# iom480ae register map
Registers are 32-bit, access not given, no defined reset value unless marked. A register's access mark holds for its fields unless they carry their own. Addresses are absolute; registers are grouped by the start of their names; [hi:lo] are bit positions; {n}, {i} and the like mark numbered series; 'fields as' and 'values as' point back to an identical list.

## EBI
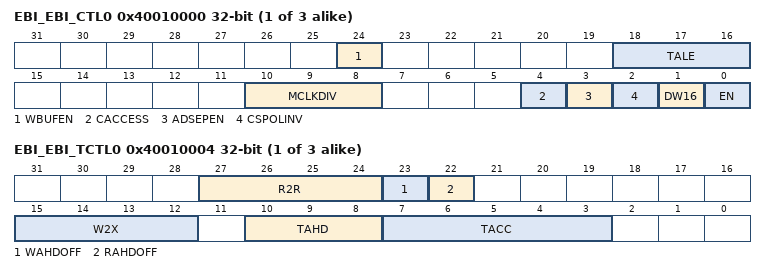
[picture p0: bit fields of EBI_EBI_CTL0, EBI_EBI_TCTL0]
{0x40010000+0x10*i} EBI_EBI_CTL{i} (i=0..2)
  [24] WBUFEN, [18:16] TALE, [10:8] MCLKDIV, [4] CACCESS, [3] ADSEPEN, [2] CSPOLINV, [1] DW16, [0] EN
{0x40010004+0x10*i} EBI_EBI_TCTL{i} (i=0..2)
  [27:24] R2R, [23] WAHDOFF, [22] RAHDOFF, [15:12] W2X, [10:8] TAHD, [7:3] TACC

## USBD
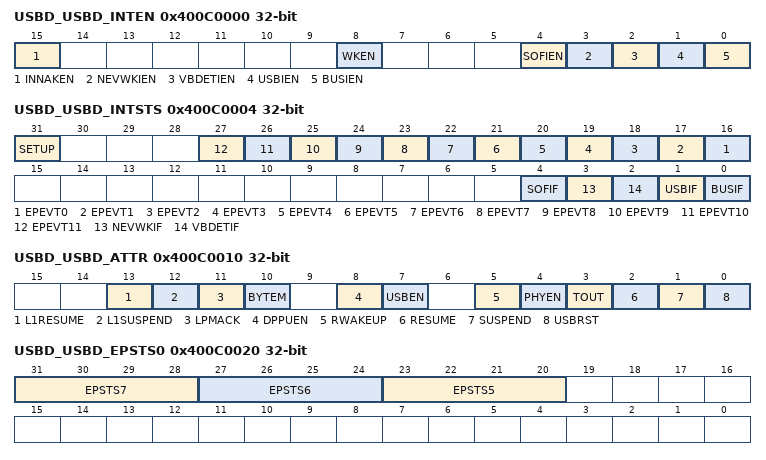
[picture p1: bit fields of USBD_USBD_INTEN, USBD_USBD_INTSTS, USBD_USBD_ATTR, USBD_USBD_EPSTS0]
0x400C0000 USBD_USBD_INTEN
  [15] INNAKEN, [8] WKEN, [4] SOFIEN, [3] NEVWKIEN, [2] VBDETIEN, [1] USBIEN, [0] BUSIEN
0x400C0004 USBD_USBD_INTSTS
  [31] SETUP, [n+16] EPEVT{n} (n=0..11), [4] SOFIF, [3] NEVWKIF, [2] VBDETIF, [1] USBIF, [0] BUSIF
0x400C0008 USBD_USBD_FADDR
  [6:0] FADDR
0x400C000C USBD_USBD_EPSTS
  [7] OV
0x400C0010 USBD_USBD_ATTR
  [13] L1RESUME, [12] L1SUSPEND, [11] LPMACK, [10] BYTEM, [8] DPPUEN, [7] USBEN, [5] RWAKEUP, [4] PHYEN, [3] TOUT, [2] RESUME, [1] SUSPEND, [0] USBRST
0x400C0014 USBD_USBD_VBUSDET
  [0] VBUSDET
0x400C0018 USBD_USBD_STBUFSEG
  [8:3] STBUFSEG
0x400C0020 USBD_USBD_EPSTS0
  [31:28] EPSTS7, [27:24] EPSTS6, [23:20] EPSTS5
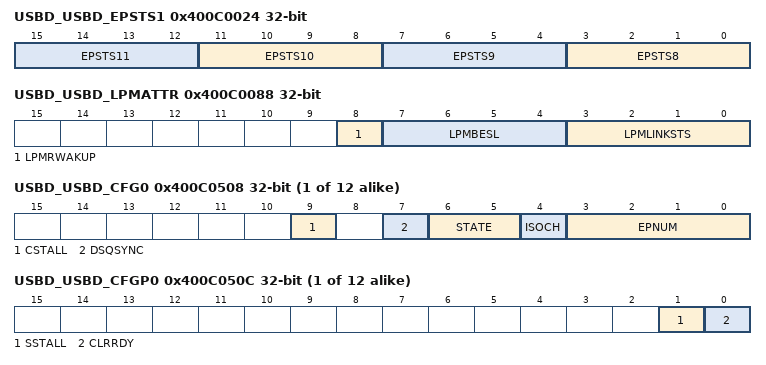
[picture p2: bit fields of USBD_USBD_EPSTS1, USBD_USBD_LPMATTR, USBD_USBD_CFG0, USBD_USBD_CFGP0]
0x400C0024 USBD_USBD_EPSTS1
  [4n-29:4n-32] EPSTS{n} (n=8..11)
0x400C0088 USBD_USBD_LPMATTR
  [8] LPMRWAKUP, [7:4] LPMBESL, [3:0] LPMLINKSTS
0x400C008C USBD_USBD_FN
  [10:0] FN
0x400C0090 USBD_USBD_SE0
  [0] SE0
{0x400C0500+0x10*i} USBD_USBD_BUFSEG{i} (i=0..11)
  [8:3] BUFSEG
{0x400C0504+0x10*i} USBD_USBD_MXPLD{i} (i=0..11)
  [8:0] MXPLD
{0x400C0508+0x10*i} USBD_USBD_CFG{i} (i=0..11)
  [9] CSTALL, [7] DSQSYNC, [6:5] STATE, [4] ISOCH, [3:0] EPNUM
{0x400C050C+0x10*i} USBD_USBD_CFGP{i} (i=0..11)
  [1] SSTALL, [0] CLRRDY

## HSUSBH
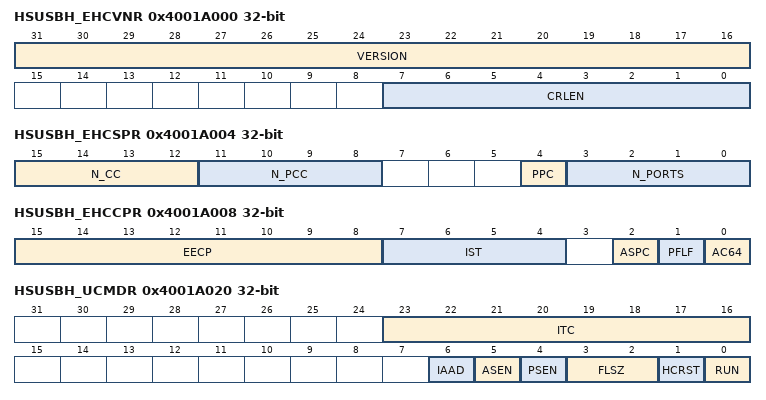
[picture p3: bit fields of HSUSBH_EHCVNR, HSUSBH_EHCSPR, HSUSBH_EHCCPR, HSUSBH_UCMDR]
0x4001A000 HSUSBH_EHCVNR
  [31:16] VERSION, [7:0] CRLEN
0x4001A004 HSUSBH_EHCSPR
  [15:12] N_CC, [11:8] N_PCC, [4] PPC, [3:0] N_PORTS
0x4001A008 HSUSBH_EHCCPR
  [15:8] EECP, [7:4] IST, [2] ASPC, [1] PFLF, [0] AC64
0x4001A020 HSUSBH_UCMDR
  [23:16] ITC, [6] IAAD, [5] ASEN, [4] PSEN, [3:2] FLSZ, [1] HCRST, [0] RUN
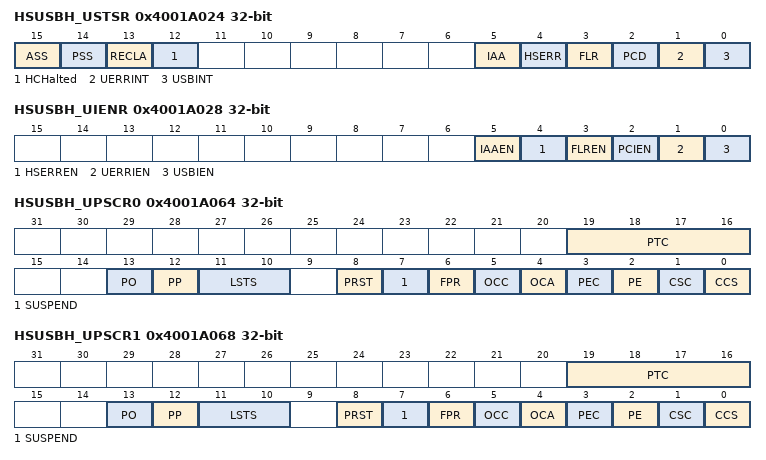
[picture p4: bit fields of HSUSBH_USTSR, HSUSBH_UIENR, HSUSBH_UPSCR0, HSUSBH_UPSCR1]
0x4001A024 HSUSBH_USTSR
  [15] ASS, [14] PSS, [13] RECLA, [12] HCHalted, [5] IAA, [4] HSERR, [3] FLR, [2] PCD, [1] UERRINT, [0] USBINT
0x4001A028 HSUSBH_UIENR
  [5] IAAEN, [4] HSERREN, [3] FLREN, [2] PCIEN, [1] UERRIEN, [0] USBIEN
0x4001A02C HSUSBH_UFINDR
  [13:0] FI
0x4001A034 HSUSBH_UPFLBAR
  [31:12] BADDR
0x4001A038 HSUSBH_UCALAR
  [31:5] LPL
0x4001A03C HSUSBH_UASSTR
  [11:0] ASSTMR
0x4001A060 HSUSBH_UCFGR
  [0] CF
0x4001A064 HSUSBH_UPSCR0
  [19:16] PTC, [13] PO, [12] PP, [11:10] LSTS, [8] PRST, [7] SUSPEND, [6] FPR, [5] OCC, [4] OCA, [3] PEC, [2] PE, [1] CSC, [0] CCS
0x4001A068 HSUSBH_UPSCR1
  fields as HSUSBH_UPSCR0
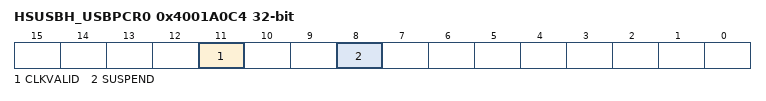
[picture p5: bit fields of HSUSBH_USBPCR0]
0x4001A0C4 HSUSBH_USBPCR0
  [11] CLKVALID, [8] SUSPEND
0x4001A0C8 HSUSBH_USBPCR1
  [8] SUSPEND

## USBH
0x40009000 USBH_HcRevision
  [7:0] REV
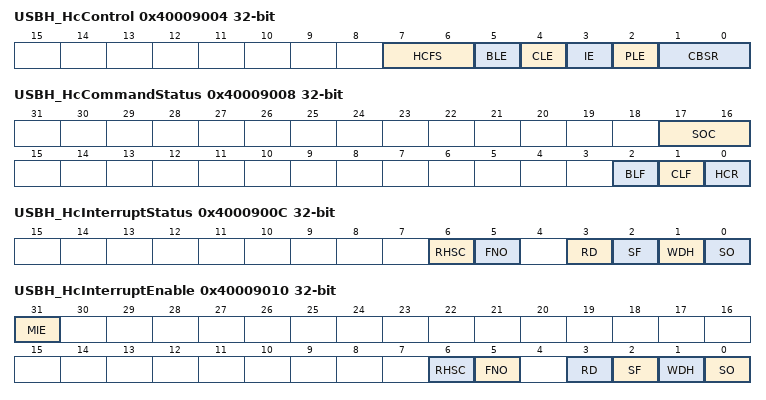
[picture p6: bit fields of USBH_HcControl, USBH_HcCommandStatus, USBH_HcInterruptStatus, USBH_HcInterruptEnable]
0x40009004 USBH_HcControl
  [7:6] HCFS, [5] BLE, [4] CLE, [3] IE, [2] PLE, [1:0] CBSR
0x40009008 USBH_HcCommandStatus
  [17:16] SOC, [2] BLF, [1] CLF, [0] HCR
0x4000900C USBH_HcInterruptStatus
  [6] RHSC, [5] FNO, [3] RD, [2] SF, [1] WDH, [0] SO
0x40009010 USBH_HcInterruptEnable
  [31] MIE, [6] RHSC, [5] FNO, [3] RD, [2] SF, [1] WDH, [0] SO
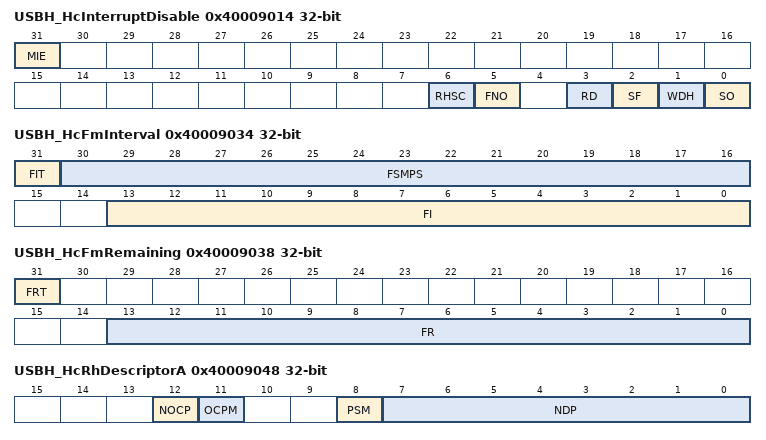
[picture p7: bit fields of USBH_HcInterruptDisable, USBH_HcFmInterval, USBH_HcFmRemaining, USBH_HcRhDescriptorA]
0x40009014 USBH_HcInterruptDisable
  [31] MIE, [6] RHSC, [5] FNO, [3] RD, [2] SF, [1] WDH, [0] SO
0x40009018 USBH_HcHCCA
  [31:8] HCCA
0x4000901C USBH_HcPeriodCurrentED
  [31:4] PCED
0x40009020 USBH_HcControlHeadED
  [31:4] CHED
0x40009024 USBH_HcControlCurrentED
  [31:4] CCED
0x40009028 USBH_HcBulkHeadED
  [31:4] BHED
0x4000902C USBH_HcBulkCurrentED
  [31:4] BCED
0x40009030 USBH_HcDoneHead
  [31:4] DH
0x40009034 USBH_HcFmInterval
  [31] FIT, [30:16] FSMPS, [13:0] FI
0x40009038 USBH_HcFmRemaining
  [31] FRT, [13:0] FR
0x4000903C USBH_HcFmNumber
  [15:0] FN
0x40009040 USBH_HcPeriodicStart
  [13:0] PS
0x40009044 USBH_HcLSThreshold
  [11:0] LST
0x40009048 USBH_HcRhDescriptorA
  [12] NOCP, [11] OCPM, [8] PSM, [7:0] NDP
0x4000904C USBH_HcRhDescriptorB
  [31:16] PPCM
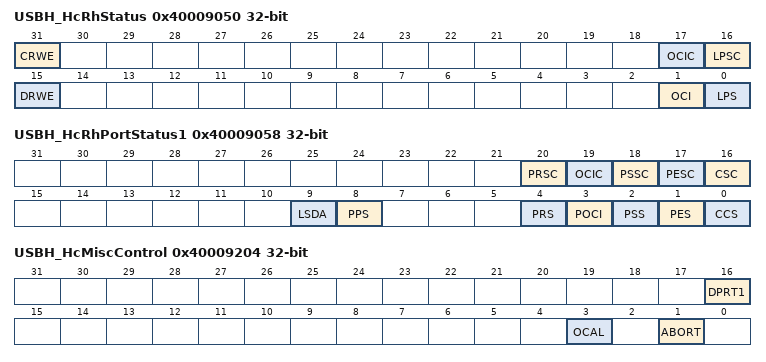
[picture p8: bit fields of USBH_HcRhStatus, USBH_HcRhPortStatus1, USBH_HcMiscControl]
0x40009050 USBH_HcRhStatus
  [31] CRWE, [17] OCIC, [16] LPSC, [15] DRWE, [1] OCI, [0] LPS
0x40009058 USBH_HcRhPortStatus1
  [20] PRSC, [19] OCIC, [18] PSSC, [17] PESC, [16] CSC, [9] LSDA, [8] PPS, [4] PRS, [3] POCI, [2] PSS, [1] PES, [0] CCS
0x40009200 USBH_HcPhyControl
  [27] STBYEN
0x40009204 USBH_HcMiscControl
  [16] DPRT1, [3] OCAL, [1] ABORT
